# HDSC_HC32M423 register map
Vendor: HDSC Co.,Ltd.; Series: ARMCM4; File version: 1.0
CPU: CM4 r0p1, little endian, MPU, FPU, 4 interrupt priority bits
Registers are 32-bit, read-write, reset 0x0 unless marked. A register's access mark holds for its fields unless they carry their own. Offsets are from the block's base; [hi:lo] are bit positions; {n}, {i} and the like mark numbered series; 'fields as' and 'values as' point back to an identical list.

## SWDT
Base 0x40049400
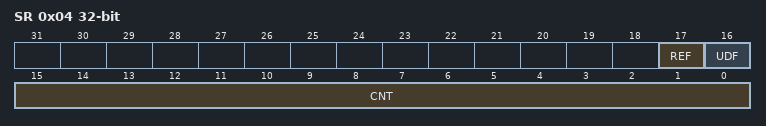
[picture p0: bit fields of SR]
0x04 SR ro
  [17] REF rw, [16] UDF rw, [15:0] CNT
0x08 RR ro
  [15:0] RF

## TMR0_1
Base 0x40024000
Same registers: TMR0_2 0x40024400
0x00 CNTAR
  [15:0] CNTA
0x04 CNTBR
  [15:0] CNTB
0x08 CMPAR reset 0xFFFF
  [15:0] CMPA
0x0C CMPBR reset 0xFFFF
  [15:0] CMPB
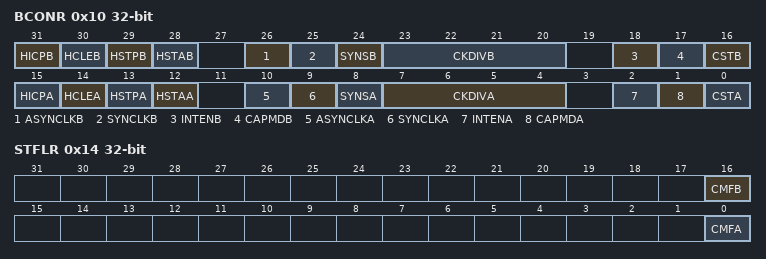
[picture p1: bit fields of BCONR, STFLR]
0x10 BCONR
  [31] HICPB, [30] HCLEB, [29] HSTPB, [28] HSTAB, [26] ASYNCLKB, [25] SYNCLKB, [24] SYNSB, [23:20] CKDIVB, [18] INTENB, [17] CAPMDB, [16] CSTB, [15] HICPA, [14] HCLEA, [13] HSTPA, [12] HSTAA, [10] ASYNCLKA, [9] SYNCLKA, [8] SYNSA, [7:4] CKDIVA, [2] INTENA, [1] CAPMDA, [0] CSTA
0x14 STFLR
  [16] CMFB, [0] CMFA

## TMRA1
Base 0x40015000
Same registers: TMRA2 0x40015400
0x00 CNTER
  [15:0] CNT
0x04 PERAR reset 0xFFFF
  [15:0] PER
0x40 CMPAR reset 0xFFFF
  [15:0] CMP
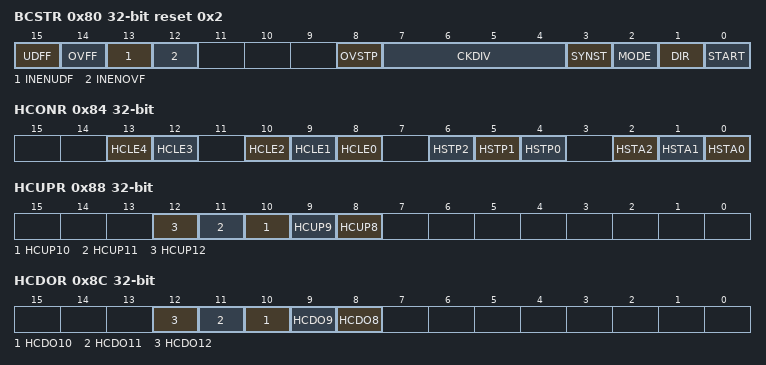
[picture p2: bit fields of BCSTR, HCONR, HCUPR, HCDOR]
0x80 BCSTR reset 0x2
  [15] UDFF, [14] OVFF, [13] INENUDF, [12] INENOVF, [8] OVSTP, [7:4] CKDIV, [3] SYNST, [2] MODE, [1] DIR, [0] START
0x84 HCONR
  [13] HCLE4, [12] HCLE3, [10] HCLE2, [9] HCLE1, [8] HCLE0, [6] HSTP2, [5] HSTP1, [4] HSTP0, [2] HSTA2, [1] HSTA1, [0] HSTA0
0x88 HCUPR
  [n] HCUP{n} (n=8..12)
0x8C HCDOR
  [n] HCDO{n} (n=8..12)
0x90 ICONR
  [0] ITEN1
0x94 ECONR
  [0] ETEN1
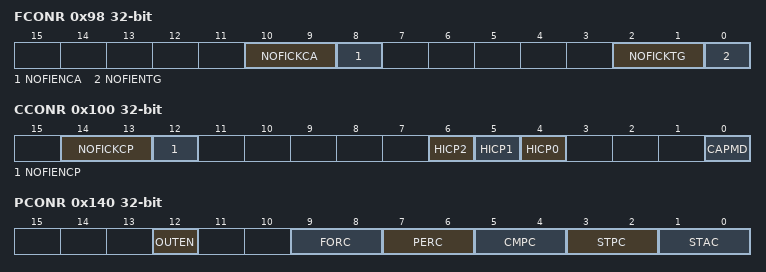
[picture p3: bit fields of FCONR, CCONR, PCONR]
0x98 FCONR
  [10:9] NOFICKCA, [8] NOFIENCA, [2:1] NOFICKTG, [0] NOFIENTG
0x9C STFLR
  [0] CMPF1
0x100 CCONR
  [14:13] NOFICKCP, [12] NOFIENCP, [6] HICP2, [5] HICP1, [4] HICP0, [0] CAPMD
0x140 PCONR
  [12] OUTEN, [9:8] FORC, [7:6] PERC, [5:4] CMPC, [3:2] STPC, [1:0] STAC

## TMRA3
Base 0x40015800
Same registers: TMRA4 0x40015C00
0x00 CNTER
  [15:0] CNT
0x04 PERAR reset 0xFFFF
  [15:0] PER
0x40 CMPAR1 reset 0xFFFF
  [15:0] CMP
0x44 CMPAR2 reset 0xFFFF
  [15:0] CMP
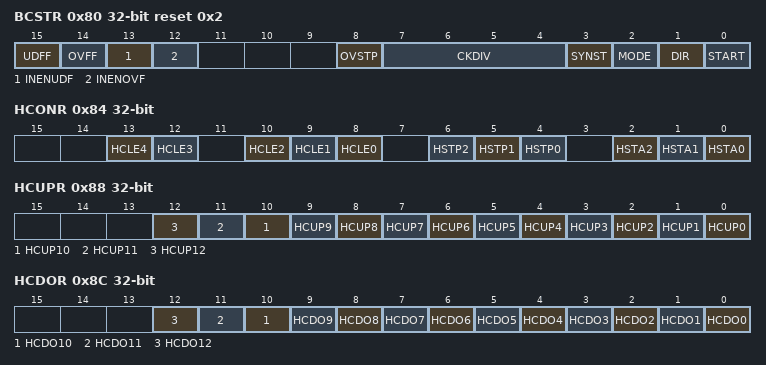
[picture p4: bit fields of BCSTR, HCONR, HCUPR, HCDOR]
0x80 BCSTR reset 0x2
  [15] UDFF, [14] OVFF, [13] INENUDF, [12] INENOVF, [8] OVSTP, [7:4] CKDIV, [3] SYNST, [2] MODE, [1] DIR, [0] START
0x84 HCONR
  [13] HCLE4, [12] HCLE3, [10] HCLE2, [9] HCLE1, [8] HCLE0, [6] HSTP2, [5] HSTP1, [4] HSTP0, [2] HSTA2, [1] HSTA1, [0] HSTA0
0x88 HCUPR
  [n] HCUP{n} (n=0..12)
0x8C HCDOR
  [n] HCDO{n} (n=0..12)
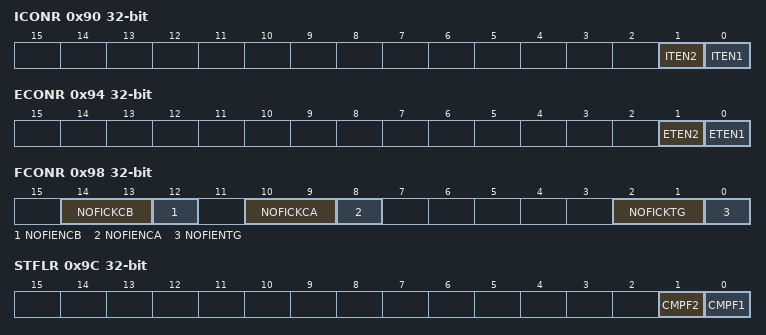
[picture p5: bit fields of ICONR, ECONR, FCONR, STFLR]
0x90 ICONR
  [1] ITEN2, [0] ITEN1
0x94 ECONR
  [1] ETEN2, [0] ETEN1
0x98 FCONR
  [14:13] NOFICKCB, [12] NOFIENCB, [10:9] NOFICKCA, [8] NOFIENCA, [2:1] NOFICKTG, [0] NOFIENTG
0x9C STFLR
  [1] CMPF2, [0] CMPF1
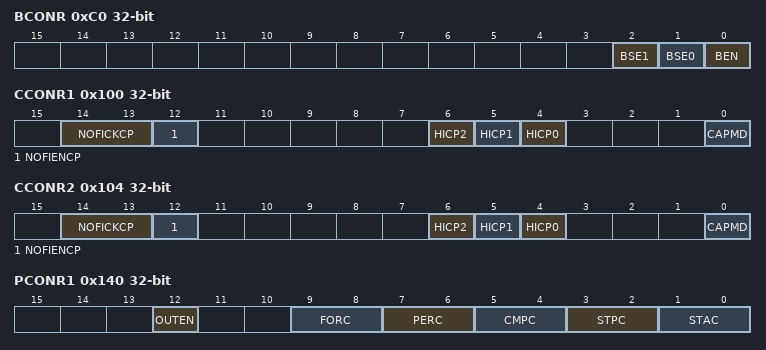
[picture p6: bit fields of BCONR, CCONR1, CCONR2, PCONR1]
0xC0 BCONR
  [2] BSE1, [1] BSE0, [0] BEN
0x100 CCONR1
  [14:13] NOFICKCP, [12] NOFIENCP, [6] HICP2, [5] HICP1, [4] HICP0, [0] CAPMD
0x104 CCONR2
  fields as CCONR1
0x140 PCONR1
  [12] OUTEN, [9:8] FORC, [7:6] PERC, [5:4] CMPC, [3:2] STPC, [1:0] STAC
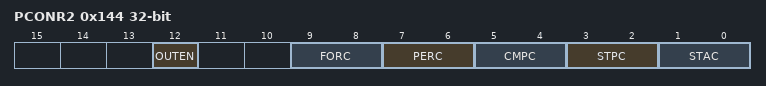
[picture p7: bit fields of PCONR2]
0x144 PCONR2
  fields as PCONR1

## TMRB
Base 0x40025000
0x00 CNTER
  [15:0] CNT
0x04 PERAR reset 0xFFFF
  [15:0] PER
{0x3C+4i} CMPAR{i} reset 0xFFFF (i=1..6)
  [15:0] CMP
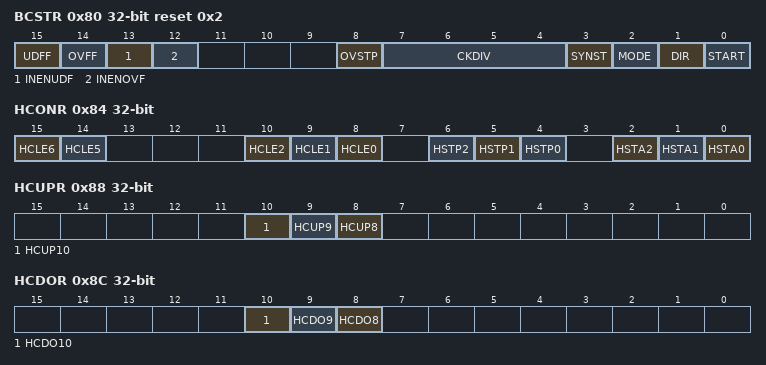
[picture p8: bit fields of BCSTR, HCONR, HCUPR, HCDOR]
0x80 BCSTR reset 0x2
  [15] UDFF, [14] OVFF, [13] INENUDF, [12] INENOVF, [8] OVSTP, [7:4] CKDIV, [3] SYNST, [2] MODE, [1] DIR, [0] START
0x84 HCONR
  [15] HCLE6, [14] HCLE5, [10] HCLE2, [9] HCLE1, [8] HCLE0, [6] HSTP2, [5] HSTP1, [4] HSTP0, [2] HSTA2, [1] HSTA1, [0] HSTA0
0x88 HCUPR
  [10] HCUP10, [9] HCUP9, [8] HCUP8
0x8C HCDOR
  [10] HCDO10, [9] HCDO9, [8] HCDO8
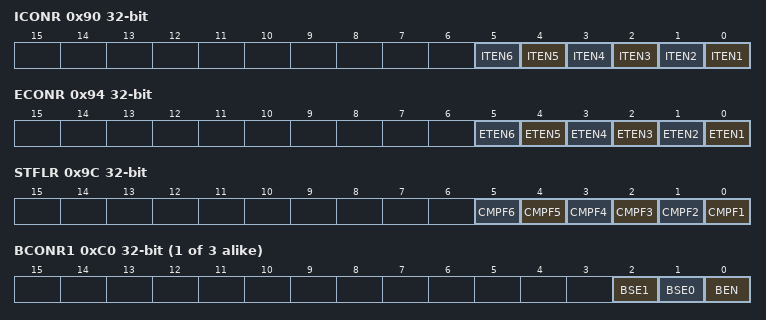
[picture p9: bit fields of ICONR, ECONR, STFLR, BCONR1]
0x90 ICONR
  [n-1] ITEN{n} (n=1..6)
0x94 ECONR
  [n-1] ETEN{n} (n=1..6)
0x9C STFLR
  [n-1] CMPF{n} (n=1..6)
{0xB8+8i} BCONR{i} (i=1..3)
  [2] BSE1, [1] BSE0, [0] BEN
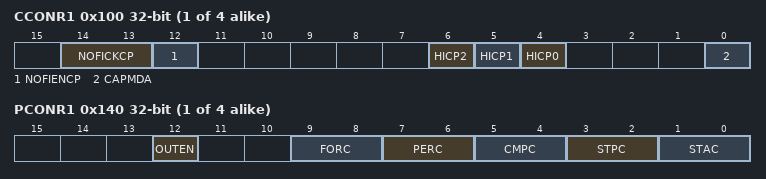
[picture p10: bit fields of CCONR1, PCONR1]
{0xFC+4i} CCONR{i} (i=1..4)
  [14:13] NOFICKCP, [12] NOFIENCP, [6] HICP2, [5] HICP1, [4] HICP0, [0] CAPMDA
{0x13C+4i} PCONR{i} (i=1..4)
  [12] OUTEN, [9:8] FORC, [7:6] PERC, [5:4] CMPC, [3:2] STPC, [1:0] STAC

## USART1
Base 0x4001D000
Same registers: USART2 0x4001D400, USART3 0x40021000, USART4 0x40021400
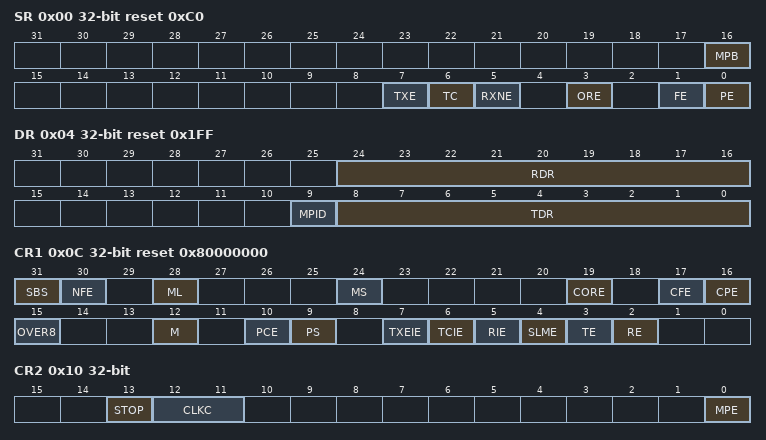
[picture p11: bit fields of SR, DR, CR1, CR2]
0x00 SR ro reset 0xC0
  [16] MPB, [7] TXE, [6] TC, [5] RXNE, [3] ORE, [1] FE, [0] PE
0x04 DR reset 0x1FF
  [24:16] RDR, [9] MPID, [8:0] TDR
0x08 BRR reset 0xFF00
  [15:8] DIV_INTEGER
0x0C CR1 reset 0x80000000
  [31] SBS, [30] NFE, [28] ML, [24] MS, [19] CORE wo, [17] CFE wo, [16] CPE wo, [15] OVER8, [12] M, [10] PCE, [9] PS, [7] TXEIE, [6] TCIE, [5] RIE, [4] SLME, [3] TE, [2] RE
0x10 CR2
  [13] STOP, [12:11] CLKC, [0] MPE
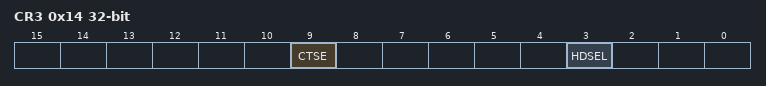
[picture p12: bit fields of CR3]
0x14 CR3
  [9] CTSE, [3] HDSEL
0x18 PR
  [1:0] PSC
